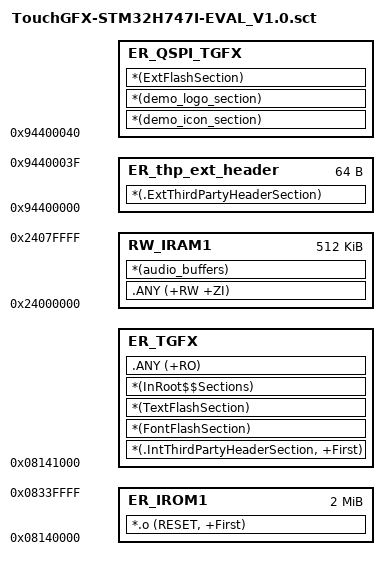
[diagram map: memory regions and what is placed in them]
; *************************************************************
; *** Scatter-Loading Description File generated by uVision ***
; *************************************************************

LR_IROM1 0x08000000 0x200000  {    ; load region size_region
  ER_IROM1 0x08140000 0x200000 {
        *.o (RESET, +First)
  }
}

LR_TGFX 0x08141000   {    ; load region size_region
  ER_TGFX 0x08141000  {
     *(.IntThirdPartyHeaderSection, +First)
   *(FontFlashSection)
   *(TextFlashSection)
    *(InRoot$$Sections)
      .ANY (+RO)    } 
  
  RW_IRAM1 0x24000000 0x80000  {  ; RW data
   .ANY (+RW +ZI)
   *(audio_buffers)
  }
}

LR_QSPI_TGFX 0x94400000 0x1E00000  {    ; load region size_region
  ER_thp_ext_header 0x94400000 0x40  {	
  *(.ExtThirdPartyHeaderSection)
     }
  ER_QSPI_TGFX 0x94400040   { 
    *(demo_icon_section)
	*(demo_logo_section)
	*(ExtFlashSection)
	}
	}
	
